# AT32F455xx_v2 register map
Vendor: Keil; Series: AT32F455; File version: 1.0
CPU: CM4 r0p1, little endian, no MPU, FPU, 4 interrupt priority bits
Registers are 32-bit, read-write, reset 0x0 unless marked. A register's access mark holds for its fields unless they carry their own. Offsets are from the block's base; [hi:lo] are bit positions.

## I2SF5 — Serial peripheral interface
Base 0x40015000
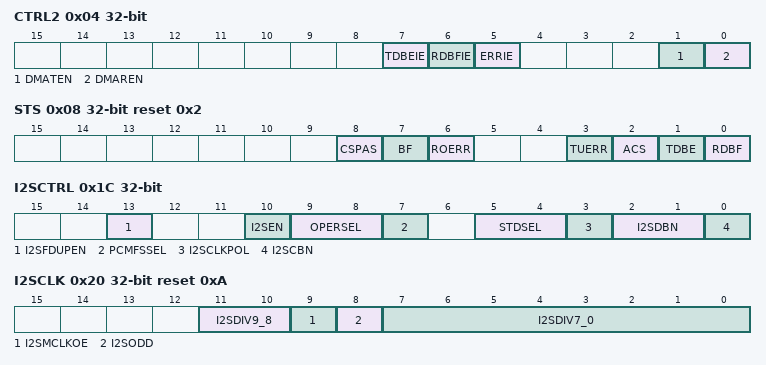
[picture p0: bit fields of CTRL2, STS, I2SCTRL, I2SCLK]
0x04 CTRL2 — control register 2
  [7] TDBEIE — Transmit data buffer empty interrupt enable
  [6] RDBFIE — Receive data buffer full interrupt enable
  [5] ERRIE — Error interrupt enable
  [1] DMATEN — DMA transmit enable
  [0] DMAREN — DMA receive enable
0x08 STS reset 0x2 — status register
  [8] CSPAS — CS pulse abnormal setting fiag
  [7] BF ro — Busy flag
  [6] ROERR ro — Receiver overflow error
  [3] TUERR ro — Transmitter underload error
  [2] ACS ro — Audio channel state
  [1] TDBE ro — Transmit data buffer empty
  [0] RDBF ro — Receive data buffer full
0x0C DT — data register
  [15:0] DT — Data value
0x1C I2SCTRL — I2S control register
  [13] I2SFDUPEN — I2S full duplex mode enable
  [10] I2SEN — I2S Enable
  [9:8] OPERSEL — I2S operation select
  [7] PCMFSSEL — PCM frame synchronization select
  [5:4] STDSEL — I2S standard select
  [3] I2SCLKPOL — I2S clock polarity
  [2:1] I2SDBN — I2S data bit num
  [0] I2SCBN — I2S channel bit num
0x20 I2SCLK reset 0xA — I2S clock register
  [11:10] I2SDIV9_8 — I2S division bit9 and bit8
  [9] I2SMCLKOE — I2S master clock output enable
  [8] I2SODD — Odd result for I2S division
  [7:0] I2SDIV7_0 — I2S division bit7 to bit0
0x30 MISC1
  [0] I2SFPCMCKSEL — I2S PCM clock edge select

## USART1 — Universal synchronous asynchronous receiver transmitter
Base 0x40011000
Same registers: USART2 0x40004400, USART3 0x40004800, USART4 0x40004C00, USART5 0x40005000, USART7 0x40007800, USART8 0x40007C00, USART6 0x40011400
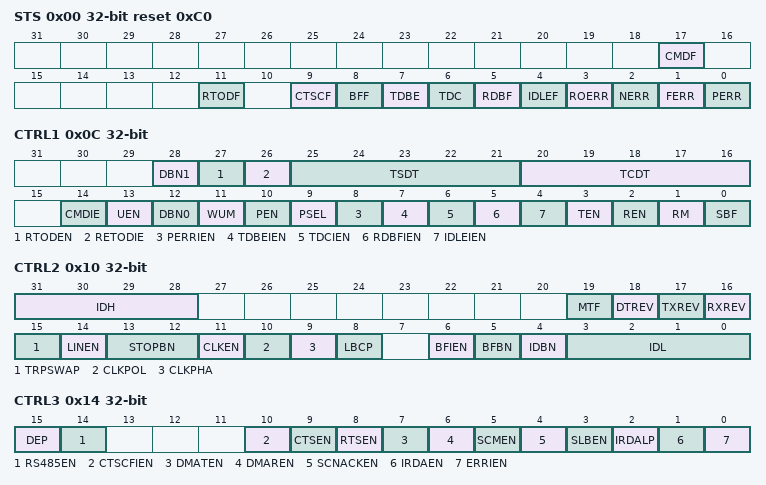
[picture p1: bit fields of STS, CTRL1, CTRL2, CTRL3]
0x00 STS reset 0xC0 — Status register
  [17] CMDF — Character match detection flag
  [11] RTODF — Receive time out detection flag
  [9] CTSCF — CTS change flag
  [8] BFF — Break frame flag
  [7] TDBE ro — Transmit data buffer empty
  [6] TDC — Transmit data complete
  [5] RDBF — Receive data buffer full
  [4] IDLEF ro — IDLE flag
  [3] ROERR ro — Receiver overflow error
  [2] NERR ro — Noise error
  [1] FERR ro — Framing error
  [0] PERR ro — Parity error
0x04 DT — Data register
  [8:0] DT — Data value
0x08 BAUDR — Baud rate register
  [15:0] DIV — Division
0x0C CTRL1 — Control register 1
  [28] DBN1 — high bit for Data bit num
  [27] RTODEN — Recevie time out detection enable
  [26] RETODIE — Recevie time out detection interrupt enable
  [25:21] TSDT — transmit start delay time
  [20:16] TCDT — transmit complete delay time
  [14] CMDIE — Character match detection interrupt enable
  [13] UEN — USART enable
  [12] DBN0 — low bit for Data bit num
  [11] WUM — Wake up mode
  [10] PEN — Parity enable
  [9] PSEL — Parity selection
  [8] PERRIEN — PERR interrupt enable
  [7] TDBEIEN — TDBE interrupt enable
  [6] TDCIEN — TDC interrupt enable
  [5] RDBFIEN — RDBF interrupt enable
  [4] IDLEIEN — IDLE interrupt enable
  [3] TEN — Transmitter enable
  [2] REN — Receiver enable
  [1] RM — Receiver mute
  [0] SBF — Send break frame
0x10 CTRL2 — Control register 2
  [31:28] IDH — bit 7-4 for usart identification
  [19] MTF — MSB transmit first
  [18] DTREV — DT register polarity reverse
  [17] TXREV — TX polarity reverse
  [16] RXREV — RX polarity reverse
  [15] TRPSWAP — Transmit receive pin swap
  [14] LINEN — LIN mode enable
  [13:12] STOPBN — STOP bit num
  [11] CLKEN — Clock enable
  [10] CLKPOL — Clock polarity
  [9] CLKPHA — Clock phase
  [8] LBCP — Last bit clock pulse
  [6] BFIEN — Break frame interrupt enable
  [5] BFBN — Break frame bit num
  [4] IDBN — Identification bit num
  [3:0] IDL — bit 3-0 for usart identification
0x14 CTRL3 — Control register 3
  [15] DEP — DE polarity selection
  [14] RS485EN — RS485 enable
  [10] CTSCFIEN — CTSCF interrupt enable
  [9] CTSEN — CTS enable
  [8] RTSEN — RTS enable
  [7] DMATEN — DMA transmitter enable
  [6] DMAREN — DMA receiver enable
  [5] SCMEN — Smartcard mode enable
  [4] SCNACKEN — Smartcard NACK enable
  [3] SLBEN — Single line bidirectional half-duplex enable
  [2] IRDALP — IrDA low-power mode
  [1] IRDAEN — IrDA enable
  [0] ERRIEN — Error interrupt enable
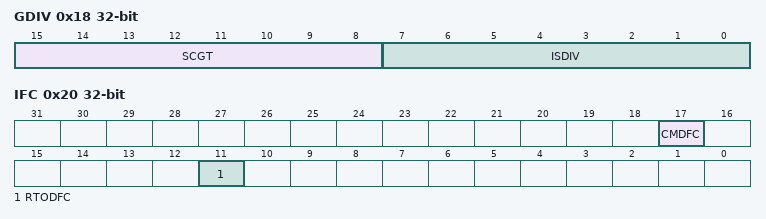
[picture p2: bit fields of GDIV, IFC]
0x18 GDIV — Guard time and division register
  [15:8] SCGT — Smart card guard time value
  [7:0] ISDIV — IrDA/smartcard division value
0x1C RTOV — Receive time out value register
  [23:0] RTOV — Receive time out value
0x20 IFC — Interrupt flag clear register
  [17] CMDFC — Character match detection flag clear
  [11] RTODFC — Receive time out detection flag clear
